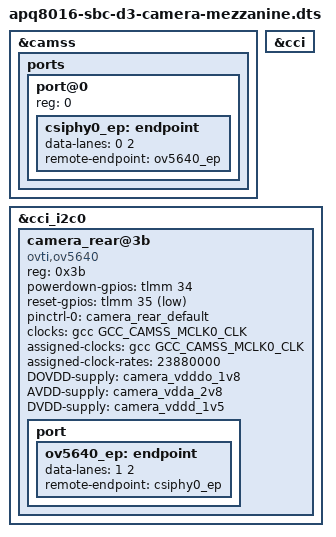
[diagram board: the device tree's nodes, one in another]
// SPDX-License-Identifier: BSD-3-Clause
/*
 * Copyright (c) 2023, Linaro Ltd.
 */

/dts-v1/;

#include "apq8016-sbc.dts"

&camss {
	status = "okay";

	ports {
		port@0 {
			reg = <0>;
			csiphy0_ep: endpoint {
				data-lanes = <0 2>;
				remote-endpoint = <&ov5640_ep>;
				status = "okay";
			};
		};
	};
};

&cci {
	status = "okay";
};

&cci_i2c0 {
	camera_rear@3b {
		compatible = "ovti,ov5640";
		reg = <0x3b>;

		powerdown-gpios = <&tlmm 34 GPIO_ACTIVE_HIGH>;
		reset-gpios = <&tlmm 35 GPIO_ACTIVE_LOW>;
		pinctrl-names = "default";
		pinctrl-0 = <&camera_rear_default>;

		clocks = <&gcc GCC_CAMSS_MCLK0_CLK>;
		clock-names = "xclk";
		assigned-clocks = <&gcc GCC_CAMSS_MCLK0_CLK>;
		assigned-clock-rates = <23880000>;

		DOVDD-supply = <&camera_vdddo_1v8>;
		AVDD-supply = <&camera_vdda_2v8>;
		DVDD-supply = <&camera_vddd_1v5>;

		port {
			ov5640_ep: endpoint {
				data-lanes = <1 2>;
				remote-endpoint = <&csiphy0_ep>;
			};
		};
	};
};
